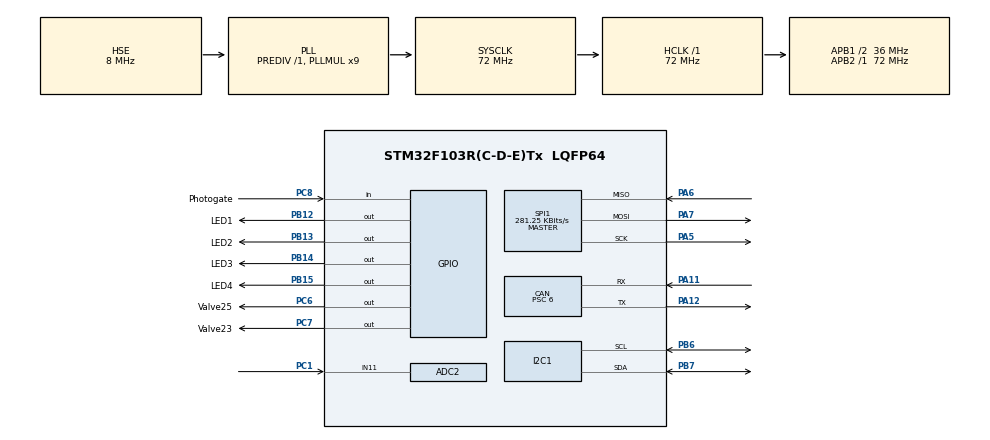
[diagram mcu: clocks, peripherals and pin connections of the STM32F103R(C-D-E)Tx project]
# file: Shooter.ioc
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ADC1.Channel-0\#ChannelRegularConversion=ADC_CHANNEL_VREFINT
ADC1.NbrOfConversionFlag=1
ADC1.Rank-0\#ChannelRegularConversion=1
ADC1.SamplingTime-0\#ChannelRegularConversion=ADC_SAMPLETIME_1CYCLE_5
ADC1.master=1
ADC2.Channel-0\#ChannelRegularConversion=ADC_CHANNEL_11
ADC2.NbrOfConversionFlag=1
ADC2.Rank-0\#ChannelRegularConversion=1
ADC2.SamplingTime-0\#ChannelRegularConversion=ADC_SAMPLETIME_1CYCLE_5
CAN.BS1=CAN_BS1_6TQ
CAN.BS2=CAN_BS2_5TQ
CAN.CalculateBaudRate=499999
CAN.CalculateTimeBit=2000
CAN.CalculateTimeQuantum=166.66666666666669
CAN.Prescaler=6
CAN.TXFP=ENABLE
Mcu.Family=STM32F1
Mcu.Name=STM32F103R(C-D-E)Tx
Mcu.Package=LQFP64
NVIC.PriorityGroup=NVIC_PRIORITYGROUP_4
NVIC.TIM4_IRQn=true\:0\:0\:false\:false\:true\:true\:true\:true
NVIC.USB_HP_CAN1_TX_IRQn=true\:0\:0\:false\:false\:true\:true\:true\:true
NVIC.USB_LP_CAN1_RX0_IRQn=true\:0\:0\:false\:false\:true\:true\:true\:true
PA11.Mode=CAN_Activate
PA11.Signal=CAN_RX
PA12.Mode=CAN_Activate
PA12.Signal=CAN_TX
PA13.Mode=Serial_Wire
PA13.Signal=SYS_JTMS-SWDIO
PA14.Mode=Serial_Wire
PA14.Signal=SYS_JTCK-SWCLK
PA5.Mode=Full_Duplex_Master
PA5.Signal=SPI1_SCK
PA6.Mode=Full_Duplex_Master
PA6.Signal=SPI1_MISO
PA7.Mode=Full_Duplex_Master
PA7.Signal=SPI1_MOSI
PB12.GPIO_Label=LED1
PB12.GPIO_PuPd=GPIO_PULLUP
PB12.Signal=GPIO_Output
PB13.GPIO_Label=LED2
PB13.GPIO_PuPd=GPIO_PULLUP
PB13.Signal=GPIO_Output
PB14.GPIO_Label=LED3
PB14.GPIO_PuPd=GPIO_PULLUP
PB14.Signal=GPIO_Output
PB15.GPIO_Label=LED4
PB15.GPIO_PuPd=GPIO_PULLUP
PB15.Signal=GPIO_Output
PB6.Mode=I2C
PB6.Signal=I2C1_SCL
PB7.Mode=I2C
PB7.Signal=I2C1_SDA
PC1.Signal=ADCx_IN11
PC6.GPIO_Label=Valve25
PC6.GPIO_PuPd=GPIO_PULLDOWN
PC6.Signal=GPIO_Output
PC7.GPIO_Label=Valve23
PC7.GPIO_PuPd=GPIO_PULLDOWN
PC7.Signal=GPIO_Output
PC8.GPIO_Label=Photogate
PC8.Signal=GPIO_Input
PD0-OSC_IN.Mode=HSE-External-Oscillator
PD0-OSC_IN.Signal=RCC_OSC_IN
PD1-OSC_OUT.Mode=HSE-External-Oscillator
PD1-OSC_OUT.Signal=RCC_OSC_OUT
ProjectManager.HeapSize=0x200
ProjectManager.StackSize=0x400
ProjectManager.TargetToolchain=CMake
RCC.ADCPresc=RCC_ADCPCLK2_DIV6
RCC.AHBFreq_Value=72000000
RCC.APB1CLKDivider=RCC_HCLK_DIV2
RCC.APB1Freq_Value=36000000
RCC.APB1TimFreq_Value=72000000
RCC.APB2Freq_Value=72000000
RCC.APB2TimFreq_Value=72000000
RCC.HCLKFreq_Value=72000000
RCC.PLLMUL=RCC_PLL_MUL9
RCC.PLLSourceVirtual=RCC_PLLSOURCE_HSE
RCC.SYSCLKFreq_VALUE=72000000
RCC.SYSCLKSource=RCC_SYSCLKSOURCE_PLLCLK
RCC.USBFreq_Value=72000000
SH.ADCx_IN11.0=ADC2_IN11,IN11
SPI1.BaudRatePrescaler=SPI_BAUDRATEPRESCALER_256
SPI1.CalculateBaudRate=281.25 KBits/s
SPI1.Direction=SPI_DIRECTION_2LINES
SPI1.Mode=SPI_MODE_MASTER
SPI1.VirtualType=VM_MASTER
TIM4.Period=1000-1
TIM4.Prescaler=36-1
VP_ADC1_TempSens_Input.Mode=IN-TempSens
VP_ADC1_Vref_Input.Mode=IN-Vrefint
VP_TIM4_VS_ClockSourceINT.Mode=Internal
board=custom

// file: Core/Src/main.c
/* USER CODE BEGIN Header */
/**
  ******************************************************************************
  * @file           : main.c
  * @brief          : Main program body
  ******************************************************************************
  * @attention
  *
  * Copyright (c) 2024 STMicroelectronics.
  * All rights reserved.
  *
  * This software is licensed under terms that can be found in the LICENSE file
  * in the root directory of this software component.
  * If no LICENSE file comes with this software, it is provided AS-IS.
  *
  ******************************************************************************
  */
/* USER CODE END Header */
#include "main.h"
#include "adc.h"
#include "can.h"
#include "i2c.h"
#include "spi.h"
#include "tim.h"
#include "gpio.h"

/* USER CODE BEGIN Includes */
#include "main.h"
#include "main_task.hpp"
/* USER CODE END Includes */

void SystemClock_Config(void);

int main(void)
{

  /* MCU Configuration--------------------------------------------------------*/

  /* Reset of all peripherals, Initializes the Flash interface and the Systick. */
  HAL_Init();

  /* Configure the system clock */
  SystemClock_Config();

  /* Initialize all configured peripherals */
  MX_GPIO_Init();
  MX_ADC1_Init();
  MX_ADC2_Init();
  MX_CAN_Init();
  MX_I2C1_Init();
  MX_TIM4_Init();
  MX_SPI1_Init();
  /* USER CODE BEGIN 2 */
  HAL_TIM_Base_Start_IT(&htim4);
  MainTaskInit();
  /* USER CODE END 2 */

  /* Infinite loop */
  while (1)
  {

  }
}

void SystemClock_Config(void)
{
  RCC_OscInitTypeDef RCC_OscInitStruct = {0};
  RCC_ClkInitTypeDef RCC_ClkInitStruct = {0};
  RCC_PeriphCLKInitTypeDef PeriphClkInit = {0};

  /** Initializes the RCC Oscillators according to the specified parameters
  * in the RCC_OscInitTypeDef structure.
  */
  RCC_OscInitStruct.OscillatorType = RCC_OSCILLATORTYPE_HSE;
  RCC_OscInitStruct.HSEState = RCC_HSE_ON;
  RCC_OscInitStruct.HSEPredivValue = RCC_HSE_PREDIV_DIV1;
  RCC_OscInitStruct.HSIState = RCC_HSI_ON;
  RCC_OscInitStruct.PLL.PLLState = RCC_PLL_ON;
  RCC_OscInitStruct.PLL.PLLSource = RCC_PLLSOURCE_HSE;
  RCC_OscInitStruct.PLL.PLLMUL = RCC_PLL_MUL9;
  if (HAL_RCC_OscConfig(&RCC_OscInitStruct) != HAL_OK)
  {
    Error_Handler();
  }

  /** Initializes the CPU, AHB and APB buses clocks
  */
  RCC_ClkInitStruct.ClockType = RCC_CLOCKTYPE_HCLK|RCC_CLOCKTYPE_SYSCLK
                              |RCC_CLOCKTYPE_PCLK1|RCC_CLOCKTYPE_PCLK2;
  RCC_ClkInitStruct.SYSCLKSource = RCC_SYSCLKSOURCE_PLLCLK;
  RCC_ClkInitStruct.AHBCLKDivider = RCC_SYSCLK_DIV1;
  RCC_ClkInitStruct.APB1CLKDivider = RCC_HCLK_DIV2;
  RCC_ClkInitStruct.APB2CLKDivider = RCC_HCLK_DIV1;

  if (HAL_RCC_ClockConfig(&RCC_ClkInitStruct, FLASH_LATENCY_2) != HAL_OK)
  {
    Error_Handler();
  }
  PeriphClkInit.PeriphClockSelection = RCC_PERIPHCLK_ADC;
  PeriphClkInit.AdcClockSelection = RCC_ADCPCLK2_DIV6;
  if (HAL_RCCEx_PeriphCLKConfig(&PeriphClkInit) != HAL_OK)
  {
    Error_Handler();
  }
}

void Error_Handler(void)
{
  __disable_irq();
  while (1)
  {
  }
}
